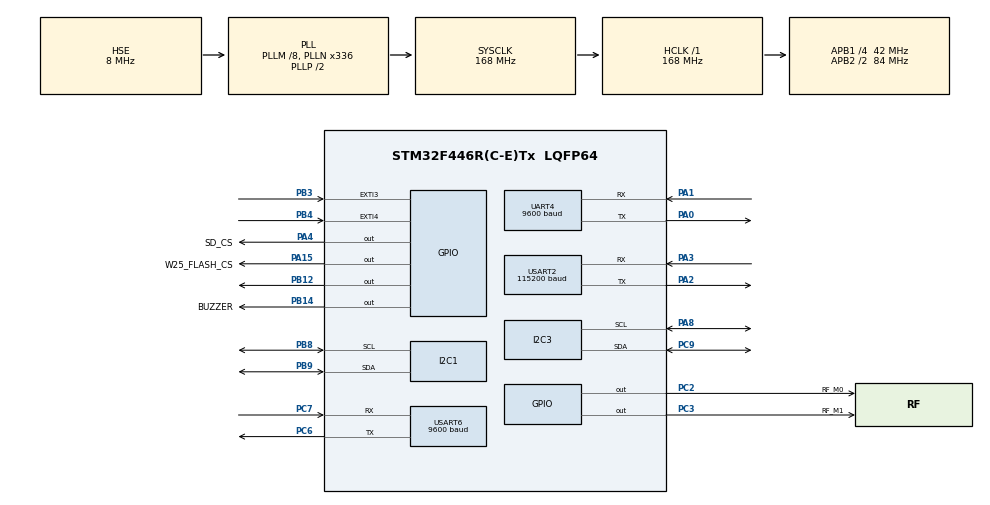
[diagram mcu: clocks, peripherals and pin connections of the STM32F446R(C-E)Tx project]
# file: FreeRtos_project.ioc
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Dma.I2C1_RX.3.Direction=DMA_PERIPH_TO_MEMORY
Dma.I2C1_RX.3.FIFOMode=DMA_FIFOMODE_DISABLE
Dma.I2C1_RX.3.Instance=DMA1_Stream0
Dma.I2C1_RX.3.MemDataAlignment=DMA_MDATAALIGN_BYTE
Dma.I2C1_RX.3.MemInc=DMA_MINC_ENABLE
Dma.I2C1_RX.3.Mode=DMA_NORMAL
Dma.I2C1_RX.3.PeriphDataAlignment=DMA_PDATAALIGN_BYTE
Dma.I2C1_RX.3.PeriphInc=DMA_PINC_DISABLE
Dma.I2C1_RX.3.Priority=DMA_PRIORITY_LOW
Dma.I2C3_RX.5.Direction=DMA_PERIPH_TO_MEMORY
Dma.I2C3_RX.5.FIFOMode=DMA_FIFOMODE_DISABLE
Dma.I2C3_RX.5.Instance=DMA1_Stream1
Dma.I2C3_RX.5.MemDataAlignment=DMA_MDATAALIGN_BYTE
Dma.I2C3_RX.5.MemInc=DMA_MINC_ENABLE
Dma.I2C3_RX.5.Mode=DMA_NORMAL
Dma.I2C3_RX.5.PeriphDataAlignment=DMA_PDATAALIGN_BYTE
Dma.I2C3_RX.5.PeriphInc=DMA_PINC_DISABLE
Dma.I2C3_RX.5.Priority=DMA_PRIORITY_LOW
Dma.Request0=USART6_RX
Dma.Request1=USART2_TX
Dma.Request2=UART4_TX
Dma.Request3=I2C1_RX
Dma.Request4=USART2_RX
Dma.Request5=I2C3_RX
Dma.UART4_TX.2.Direction=DMA_MEMORY_TO_PERIPH
Dma.UART4_TX.2.FIFOMode=DMA_FIFOMODE_DISABLE
Dma.UART4_TX.2.Instance=DMA1_Stream4
Dma.UART4_TX.2.MemDataAlignment=DMA_MDATAALIGN_BYTE
Dma.UART4_TX.2.MemInc=DMA_MINC_ENABLE
Dma.UART4_TX.2.Mode=DMA_NORMAL
Dma.UART4_TX.2.PeriphDataAlignment=DMA_PDATAALIGN_BYTE
Dma.UART4_TX.2.PeriphInc=DMA_PINC_DISABLE
Dma.UART4_TX.2.Priority=DMA_PRIORITY_LOW
Dma.USART2_RX.4.Direction=DMA_PERIPH_TO_MEMORY
Dma.USART2_RX.4.FIFOMode=DMA_FIFOMODE_DISABLE
Dma.USART2_RX.4.Instance=DMA1_Stream5
Dma.USART2_RX.4.MemDataAlignment=DMA_MDATAALIGN_BYTE
Dma.USART2_RX.4.MemInc=DMA_MINC_ENABLE
Dma.USART2_RX.4.Mode=DMA_NORMAL
Dma.USART2_RX.4.PeriphDataAlignment=DMA_PDATAALIGN_BYTE
Dma.USART2_RX.4.PeriphInc=DMA_PINC_DISABLE
Dma.USART2_RX.4.Priority=DMA_PRIORITY_LOW
Dma.USART2_TX.1.Direction=DMA_MEMORY_TO_PERIPH
Dma.USART2_TX.1.FIFOMode=DMA_FIFOMODE_DISABLE
Dma.USART2_TX.1.Instance=DMA1_Stream6
Dma.USART2_TX.1.MemDataAlignment=DMA_MDATAALIGN_BYTE
Dma.USART2_TX.1.MemInc=DMA_MINC_ENABLE
Dma.USART2_TX.1.Mode=DMA_NORMAL
Dma.USART2_TX.1.PeriphDataAlignment=DMA_PDATAALIGN_BYTE
Dma.USART2_TX.1.PeriphInc=DMA_PINC_DISABLE
Dma.USART2_TX.1.Priority=DMA_PRIORITY_LOW
Dma.USART6_RX.0.Direction=DMA_PERIPH_TO_MEMORY
Dma.USART6_RX.0.FIFOMode=DMA_FIFOMODE_DISABLE
Dma.USART6_RX.0.Instance=DMA2_Stream2
Dma.USART6_RX.0.MemDataAlignment=DMA_MDATAALIGN_BYTE
Dma.USART6_RX.0.MemInc=DMA_MINC_ENABLE
Dma.USART6_RX.0.Mode=DMA_CIRCULAR
Dma.USART6_RX.0.PeriphDataAlignment=DMA_PDATAALIGN_BYTE
Dma.USART6_RX.0.PeriphInc=DMA_PINC_DISABLE
Dma.USART6_RX.0.Priority=DMA_PRIORITY_LOW
FREERTOS.Tasks01=defaultTask,24,128,StartDefaultTask,Default,NULL,Dynamic,NULL,NULL
FREERTOS.configENABLE_FPU=1
Mcu.Family=STM32F4
Mcu.Name=STM32F446R(C-E)Tx
Mcu.Package=LQFP64
NVIC.DMA1_Stream0_IRQn=true\:5\:0\:false\:false\:true\:true\:false\:true\:true
NVIC.DMA1_Stream1_IRQn=true\:5\:0\:false\:false\:true\:true\:false\:true\:true
NVIC.DMA1_Stream4_IRQn=true\:5\:0\:false\:false\:true\:true\:false\:true\:true
NVIC.DMA1_Stream5_IRQn=true\:5\:0\:false\:false\:true\:true\:false\:true\:true
NVIC.DMA1_Stream6_IRQn=true\:5\:0\:false\:false\:true\:true\:false\:true\:true
NVIC.DMA2_Stream2_IRQn=true\:5\:0\:false\:false\:true\:true\:false\:true\:true
NVIC.EXTI3_IRQn=true\:5\:0\:false\:false\:true\:true\:true\:true\:true
NVIC.EXTI4_IRQn=true\:5\:0\:false\:false\:true\:true\:true\:true\:true
NVIC.I2C1_EV_IRQn=true\:5\:0\:false\:false\:true\:true\:true\:true\:true
NVIC.I2C3_EV_IRQn=true\:5\:0\:false\:false\:true\:true\:true\:true\:true
NVIC.PriorityGroup=NVIC_PRIORITYGROUP_4
NVIC.TIM2_IRQn=true\:5\:0\:false\:false\:true\:true\:true\:true\:true
NVIC.TIM6_DAC_IRQn=true\:15\:0\:false\:false\:true\:false\:false\:true\:true
NVIC.TimeBase=TIM6_DAC_IRQn
NVIC.TimeBaseIP=TIM6
NVIC.UART4_IRQn=true\:5\:0\:false\:false\:true\:true\:true\:true\:true
NVIC.USART2_IRQn=true\:5\:0\:false\:false\:true\:true\:true\:true\:true
NVIC.USART6_IRQn=true\:5\:0\:false\:false\:true\:true\:true\:true\:true
PA0-WKUP.Mode=Asynchronous
PA0-WKUP.Signal=UART4_TX
PA1.Mode=Asynchronous
PA1.Signal=UART4_RX
PA13.Mode=Serial_Wire
PA13.Signal=SYS_JTMS-SWDIO
PA14.Mode=Serial_Wire
PA14.Signal=SYS_JTCK-SWCLK
PA15.GPIO_Label=W25_FLASH_CS
PA15.Signal=GPIO_Output
PA2.Mode=Asynchronous
PA2.Signal=USART2_TX
PA3.Mode=Asynchronous
PA3.Signal=USART2_RX
PA4.GPIO_Label=SD_CS
PA4.Signal=GPIO_Output
PA8.GPIO_Pu=GPIO_NOPULL
PA8.Mode=I2C
PA8.Signal=I2C3_SCL
PB1.Signal=ADCx_IN9
PB12.GPIO_Speed=GPIO_SPEED_FREQ_VERY_HIGH
PB12.Signal=GPIO_Output
PB14.GPIO_Label=BUZZER
PB14.Signal=GPIO_Output
PB3.Signal=GPXTI3
PB4.Signal=GPXTI4
PB8.Mode=I2C
PB8.Signal=I2C1_SCL
PB9.Mode=I2C
PB9.Signal=I2C1_SDA
PC0.Signal=ADCx_IN10
PC1.Signal=ADCx_IN11
PC12.Signal=SPI3_MOSI
PC14-OSC32_IN.Mode=LSE-External-Oscillator
PC14-OSC32_IN.Signal=RCC_OSC32_IN
PC15-OSC32_OUT.Mode=LSE-External-Oscillator
PC15-OSC32_OUT.Signal=RCC_OSC32_OUT
PC2.GPIO_Label=RF_M0
PC2.Signal=GPIO_Output
PC3.GPIO_Label=RF_M1
PC3.Signal=GPIO_Output
PC6.Mode=Asynchronous
PC6.Signal=USART6_TX
PC7.Mode=Asynchronous
PC7.Signal=USART6_RX
PC9.GPIO_Pu=GPIO_NOPULL
PC9.Mode=I2C
PC9.Signal=I2C3_SDA
PH0-OSC_IN.Mode=HSE-External-Oscillator
PH0-OSC_IN.Signal=RCC_OSC_IN
PH1-OSC_OUT.Mode=HSE-External-Oscillator
PH1-OSC_OUT.Signal=RCC_OSC_OUT
ProjectManager.HeapSize=0x200
ProjectManager.StackSize=0x400
ProjectManager.TargetToolchain=CMake
RCC.AHBFreq_Value=168000000
RCC.APB1CLKDivider=RCC_HCLK_DIV4
RCC.APB1Freq_Value=42000000
RCC.APB1TimFreq_Value=84000000
RCC.APB2CLKDivider=RCC_HCLK_DIV2
RCC.APB2Freq_Value=84000000
RCC.APB2TimFreq_Value=168000000
RCC.CortexFreq_Value=168000000
RCC.HCLKFreq_Value=168000000
RCC.HSE_VALUE=8000000
RCC.PLLM=8
RCC.PLLN=336
RCC.PLLSourceVirtual=RCC_PLLSOURCE_HSE
RCC.SYSCLKFreq_VALUE=168000000
RCC.SYSCLKSource=RCC_SYSCLKSOURCE_PLLCLK
RCC.USBFreq_Value=168000000
RCC.VCOOutputFreq_Value=336000000
SH.ADCx_IN10.0=ADC2_IN10
SH.ADCx_IN11.0=ADC3_IN11
SH.ADCx_IN9.0=ADC1_IN9
TIM2.Period=999
TIM2.Prescaler=8399
UART4.BaudRate=9600
UART4.VirtualMode=Asynchronous
USART2.BaudRate=115200
USART2.VirtualMode=VM_ASYNC
USART6.BaudRate=9600
USART6.VirtualMode=VM_ASYNC
VP_FREERTOS_VS_CMSIS_V2.Mode=CMSIS_V2
VP_SYS_VS_tim6.Mode=TIM6
VP_TIM2_VS_ClockSourceINT.Mode=Internal
board=custom

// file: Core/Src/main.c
/* USER CODE BEGIN Header */
/**
  ******************************************************************************
  * @file           : main.c
  * @brief          : Main program body
  ******************************************************************************
  * @attention
  *
  * Copyright (c) 2026 STMicroelectronics.
  * All rights reserved.
  *
  * This software is licensed under terms that can be found in the LICENSE file
  * in the root directory of this software component.
  * If no LICENSE file comes with this software, it is provided AS-IS.
  *
  ******************************************************************************
  */
/* USER CODE END Header */
#include "main.h"
#include "cmsis_os.h"
#include "dma.h"
#include "i2c.h"
#include "iwdg.h"
#include "tim.h"
#include "usart.h"
#include "gpio.h"

void SystemClock_Config(void);
void MX_FREERTOS_Init(void);

int main(void)
{

  /* MCU Configuration--------------------------------------------------------*/

  /* Reset of all peripherals, Initializes the Flash interface and the Systick. */
  HAL_Init();

  /* Configure the system clock */
  SystemClock_Config();

  /* Initialize all configured peripherals */
  MX_GPIO_Init();
  MX_DMA_Init();
  MX_I2C1_Init();
  MX_I2C3_Init();
  MX_TIM2_Init();
  MX_USART2_UART_Init();
  MX_USART6_UART_Init();
  MX_UART4_Init();
  MX_IWDG_Init();

  /* Init scheduler */
  osKernelInitialize();  /* Call init function for freertos objects (in cmsis_os2.c) */
  MX_FREERTOS_Init();

  /* Start scheduler */
  osKernelStart();

  /* We should never get here as control is now taken by the scheduler */

  /* Infinite loop */
  while (1)
  {

  }
}

void SystemClock_Config(void)
{
  RCC_OscInitTypeDef RCC_OscInitStruct = {0};
  RCC_ClkInitTypeDef RCC_ClkInitStruct = {0};

  /** Configure the main internal regulator output voltage
  */
  __HAL_RCC_PWR_CLK_ENABLE();
  __HAL_PWR_VOLTAGESCALING_CONFIG(PWR_REGULATOR_VOLTAGE_SCALE1);

  /** Initializes the RCC Oscillators according to the specified parameters
  * in the RCC_OscInitTypeDef structure.
  */
  RCC_OscInitStruct.OscillatorType = RCC_OSCILLATORTYPE_LSI|RCC_OSCILLATORTYPE_HSE;
  RCC_OscInitStruct.HSEState = RCC_HSE_ON;
  RCC_OscInitStruct.LSIState = RCC_LSI_ON;
  RCC_OscInitStruct.PLL.PLLState = RCC_PLL_ON;
  RCC_OscInitStruct.PLL.PLLSource = RCC_PLLSOURCE_HSE;
  RCC_OscInitStruct.PLL.PLLM = 8;
  RCC_OscInitStruct.PLL.PLLN = 336;
  RCC_OscInitStruct.PLL.PLLP = RCC_PLLP_DIV2;
  RCC_OscInitStruct.PLL.PLLQ = 2;
  RCC_OscInitStruct.PLL.PLLR = 2;
  if (HAL_RCC_OscConfig(&RCC_OscInitStruct) != HAL_OK)
  {
    Error_Handler();
  }

  /** Initializes the CPU, AHB and APB buses clocks
  */
  RCC_ClkInitStruct.ClockType = RCC_CLOCKTYPE_HCLK|RCC_CLOCKTYPE_SYSCLK
                              |RCC_CLOCKTYPE_PCLK1|RCC_CLOCKTYPE_PCLK2;
  RCC_ClkInitStruct.SYSCLKSource = RCC_SYSCLKSOURCE_PLLCLK;
  RCC_ClkInitStruct.AHBCLKDivider = RCC_SYSCLK_DIV1;
  RCC_ClkInitStruct.APB1CLKDivider = RCC_HCLK_DIV4;
  RCC_ClkInitStruct.APB2CLKDivider = RCC_HCLK_DIV2;

  if (HAL_RCC_ClockConfig(&RCC_ClkInitStruct, FLASH_LATENCY_5) != HAL_OK)
  {
    Error_Handler();
  }
}

void HAL_TIM_PeriodElapsedCallback(TIM_HandleTypeDef *htim)
{
  if (htim->Instance == TIM6)
  {
    HAL_IncTick();
  }
}

void Error_Handler(void)
{
  /* USER CODE BEGIN Error_Handler_Debug */
  __disable_irq();
  NVIC_SystemReset();
  /* USER CODE END Error_Handler_Debug */
}

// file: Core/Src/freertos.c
/* USER CODE BEGIN Header */
/**
  ******************************************************************************
  * File Name          : freertos.c
  * Description        : Code for freertos applications
  ******************************************************************************
  * @attention
  *
  * Copyright (c) 2026 STMicroelectronics.
  * All rights reserved.
  *
  * This software is licensed under terms that can be found in the LICENSE file
  * in the root directory of this software component.
  * If no LICENSE file comes with this software, it is provided AS-IS.
  *
  ******************************************************************************
  */
/* USER CODE END Header */

#include "FreeRTOS.h"
#include "task.h"
#include "main.h"
#include "cmsis_os.h"

/* USER CODE BEGIN Includes */
#include "app.h"
/* USER CODE END Includes */

/* Definitions for defaultTask */
osThreadId_t defaultTaskHandle;
const osThreadAttr_t defaultTask_attributes = {
  .name = "defaultTask",
  .stack_size = 128 * 4,
  .priority = (osPriority_t) osPriorityNormal,
};

void StartDefaultTask(void *argument);

void MX_FREERTOS_Init(void); /* (MISRA C 2004 rule 8.1) */

void MX_FREERTOS_Init(void) {

  /* Create the thread(s) */
  /* creation of defaultTask */
  defaultTaskHandle = osThreadNew(StartDefaultTask, NULL, &defaultTask_attributes);

  /* USER CODE BEGIN RTOS_THREADS */
  Application_Start();
  /* USER CODE END RTOS_THREADS */

}

void StartDefaultTask(void *argument)
{
  /* USER CODE BEGIN StartDefaultTask */
  /* Infinite loop */
	  SEGGER_SYSVIEW_Start();

  for(;;)
  {
    osDelay(100000);
  }
  /* USER CODE END StartDefaultTask */
}
